# CPSW1_COMMON_0_NUSS register map
Vendor: Texas Instruments
Peripheral module from a debugger description file (folder J7_AHP).
Registers are 32-bit, read-write, reset 0x0 unless marked. A register's access mark holds for its fields unless they carry their own. Offsets are as the file gives them; lines under a group give offsets from that group; [hi:lo] are bit positions; {n}, {i} and the like mark numbered series; 'fields as' and 'values as' point back to an identical list; <NAME> marks a mode.

## CPSW1_COMMON_0_NUSS (part 1 of 2)
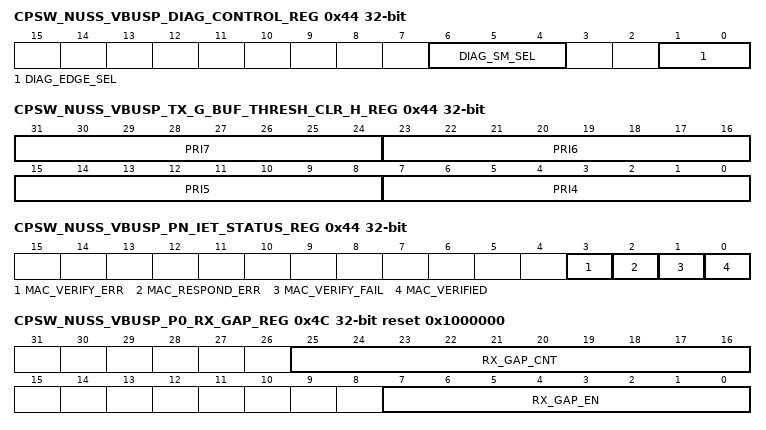
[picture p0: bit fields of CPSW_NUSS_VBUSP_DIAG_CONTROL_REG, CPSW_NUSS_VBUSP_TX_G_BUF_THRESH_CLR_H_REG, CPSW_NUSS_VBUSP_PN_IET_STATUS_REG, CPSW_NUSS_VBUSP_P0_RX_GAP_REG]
0x44 CPSW_NUSS_VBUSP_DIAG_CONTROL_REG
  [6:4] DIAG_SM_SEL — Diagnostic select
  [1:0] DIAG_EDGE_SEL — Diagnostics hold signals edge select
0x44 CPSW_NUSS_VBUSP_USER_ADDR1_REG
  [15:0] USER_ADDR1 — MDIO USER Address 1
0x44 CPSW_NUSS_VBUSP_TX_G_BUF_THRESH_CLR_H_REG
  [8n-25:8n-32] PRI{n} (n=4..7) — Priority Based Flow Control Global Buffer Usage Threshold for Priority {n}
0x44 CPSW_NUSS_VBUSP_PN_IET_STATUS_REG ro
  [3] MAC_VERIFY_ERR — IET MAC VERIFY ERROR
  [2] MAC_RESPOND_ERR — IET MAC RESPONSE ERROR
  [1] MAC_VERIFY_FAIL — IET MAC VERIFY FAIL
  [0] MAC_VERIFIED — IET MAC VERIFIED
0x44 CPSW_NUSS_VBUSP_TXDEFERREDFRAMES
  [31:0] COUNT — Total number of deferred frames transmitted
0x44 CPSW_NUSS_VBUSP_TS_LOAD_HIGH_VAL_REG
  [31:0] TS_LOAD_VAL — Time stamp load high value
0x48 CPSW_NUSS_VBUSP_DIAG_STATUS_REG ro
  [15:0] DIAG_STATUS — Diagnostics status
0x48 CPSW_NUSS_VBUSP_PN_IET_VERIFY_REG reset 0x1312D0
  [23:0] MAC_VERIFY_CNT — IET MAC VERIFY COUNT
0x48 CPSW_NUSS_VBUSP_TXCOLLISIONFRAMES
  [31:0] COUNT — Total number of transmitted frames experiencing a collision
0x48 CPSW_NUSS_VBUSP_TS_COMP_HIGH_VAL_REG
  [31:0] TS_COMP_HIGH_VAL — Time stamp comparison high value
0x4C CPSW_NUSS_VBUSP_P0_RX_GAP_REG reset 0x1000000
  [25:16] RX_GAP_CNT — Port 0 Receive Gap Count
  [7:0] RX_GAP_EN — Port 0 Receive Gap Enable
0x4C CPSW_NUSS_VBUSP_TXSINGLECOLLFRAMES
  [31:0] COUNT — Total number of transmitted frames experiencing a single collision
0x4C CPSW_NUSS_VBUSP_TS_ADD_VAL_REG
  [2:0] ADD_VAL — Add Value
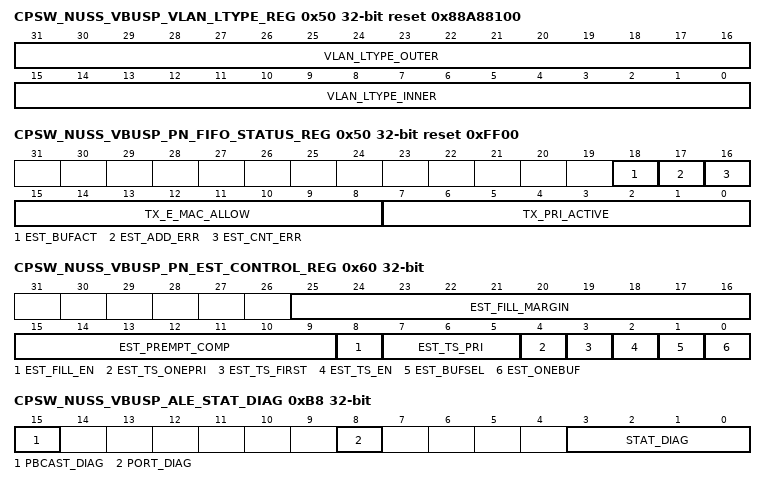
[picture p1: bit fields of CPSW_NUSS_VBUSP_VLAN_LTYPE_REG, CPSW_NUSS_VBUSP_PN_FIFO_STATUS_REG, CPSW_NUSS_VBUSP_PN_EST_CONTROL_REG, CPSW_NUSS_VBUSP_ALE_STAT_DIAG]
0x50 CPSW_NUSS_VBUSP_VLAN_LTYPE_REG reset 0x88A88100
  [31:16] VLAN_LTYPE_OUTER — Outer VLAN LType
  [15:0] VLAN_LTYPE_INNER — Inner VLAN LType
0x50 CPSW_NUSS_VBUSP_P0_FIFO_STATUS_REG ro
  [7:0] TX_PRI_ACTIVE — Port 0 FIFO Status
0x50 CPSW_NUSS_VBUSP_PN_FIFO_STATUS_REG ro reset 0xFF00
  [18] EST_BUFACT — Transmit FIFO EST Buffer Active
  [17] EST_ADD_ERR — Transmit FIFO EST Address Error
  [16] EST_CNT_ERR — Transmit FIFO EST Count Error
  [15:8] TX_E_MAC_ALLOW — Transmit FIFO Express Queue Priority Allow
  [7:0] TX_PRI_ACTIVE — Transmit FIFO Priority Active
0x50 CPSW_NUSS_VBUSP_TXMULTCOLLFRAMES
  [31:0] COUNT — Total number of transmitted frames experiencing multiple collisions
0x50 CPSW_NUSS_VBUSP_TS_PPM_LOW_VAL_REG
  [31:0] TS_PPM_LOW_VAL — Time stamp PPM Low value
0x54 CPSW_NUSS_VBUSP_EST_TS_DOMAIN_REG
  [7:0] EST_TS_DOMAIN — Enhanced Scheduled Traffic Host Event Domain
0x54 CPSW_NUSS_VBUSP_TXEXCESSIVECOLLISIONS
  [31:0] COUNT — Total number of transmitted frames abandoned due to excessive collisions
0x54 CPSW_NUSS_VBUSP_TS_PPM_HIGH_VAL_REG
  [9:0] TS_PPM_HIGH_VAL — Time stamp PPM High value
0x58 CPSW_NUSS_VBUSP_TXLATECOLLISIONS
  [31:0] COUNT — Total number of transmitted frames abandoned due to a late collision
0x58 CPSW_NUSS_VBUSP_TS_NUDGE_VAL_REG
  [7:0] TS_NUDGE_VAL — Time stamp Nudge value
0x5C CPSW_NUSS_VBUSP_RXIPGERROR
  [31:0] COUNT — Total number of receive inter-packet gap errors (10G only)
0x60 CPSW_NUSS_VBUSP_PN_EST_CONTROL_REG
  [25:16] EST_FILL_MARGIN — Transmit FIFO EST Fill Margin
  [15:9] EST_PREMPT_COMP — Transmit FIFO EST Prempt Comparision Value
  [8] EST_FILL_EN — Transmit FIFO EST Fill Enable
  [7:5] EST_TS_PRI — Transmit FIFO EST TimeStamp Priority
  [4] EST_TS_ONEPRI — Transmit FIFO EST TimeStamp One Priority
  [3] EST_TS_FIRST — Transmit FIFO EST TimeStamp First Express Packet
  [2] EST_TS_EN — Transmit FIFO EST TimeStamp Enable
  [1] EST_BUFSEL — Transmit FIFO EST Buffer Select
  [0] EST_ONEBUF — Transmit FIFO EST One Buffer
0x60 CPSW_NUSS_VBUSP_TXCARRIERSENSEERRORS
  [31:0] COUNT — Total number of transmitted frames that experienced a carrier loss
0x64 CPSW_NUSS_VBUSP_TXOCTETS
  [31:0] COUNT — Total number of bytes in all good frames transmitted
0x64 CPSW_NUSS_VBUSP_TXOCTETS
  [31:0] COUNT — Total number of bytes in all good frames transmitted
0x68 CPSW_NUSS_VBUSP_OCTETFRAMES64
  [31:0] COUNT — Total number of 64-byte frames received and transmitted
0x68 CPSW_NUSS_VBUSP_OCTETFRAMES64
  fields as CPSW_NUSS_VBUSP_OCTETFRAMES64
0x6C CPSW_NUSS_VBUSP_OCTETFRAMES65T127
  [31:0] COUNT — Total number of frames of size 65 to 127 bytes received and transmitted
0x6C CPSW_NUSS_VBUSP_OCTETFRAMES65T127
  fields as CPSW_NUSS_VBUSP_OCTETFRAMES65T127
0x70 CPSW_NUSS_VBUSP_OCTETFRAMES128T255
  [31:0] COUNT — Total number of frames of size 128 to 255 bytes received and transmitted
0x70 CPSW_NUSS_VBUSP_OCTETFRAMES128T255
  fields as CPSW_NUSS_VBUSP_OCTETFRAMES128T255
0x74 CPSW_NUSS_VBUSP_OCTETFRAMES256T511
  [31:0] COUNT — Total number of frames of size 256 to 511 bytes received and transmitted
0x74 CPSW_NUSS_VBUSP_OCTETFRAMES256T511
  fields as CPSW_NUSS_VBUSP_OCTETFRAMES256T511
0x78 CPSW_NUSS_VBUSP_OCTETFRAMES512T1023
  [31:0] COUNT — Total number of frames of size 512 to 1023 bytes received and transmitted
0x78 CPSW_NUSS_VBUSP_OCTETFRAMES512T1023
  fields as CPSW_NUSS_VBUSP_OCTETFRAMES512T1023
0x7C CPSW_NUSS_VBUSP_OCTETFRAMES1024TUP
  [31:0] COUNT — Total number of frames of size 1024 to rx_maxlen bytes received and 1024 bytes or greater transmitted
0x7C CPSW_NUSS_VBUSP_OCTETFRAMES1024TUP
  fields as CPSW_NUSS_VBUSP_OCTETFRAMES1024TUP
0x80 CPSW_NUSS_VBUSP_NETOCTETS
  [31:0] COUNT — Total number of bytes received and transmitted
0x80 CPSW_NUSS_VBUSP_NETOCTETS
  [31:0] COUNT — Total number of bytes received and transmitted
0x84 CPSW_NUSS_VBUSP_RX_BOTTOM_OF_FIFO_DROP
  [31:0] COUNT — Receive Bottom of FIFO Drop
0x84 CPSW_NUSS_VBUSP_RX_BOTTOM_OF_FIFO_DROP
  [31:0] COUNT — Receive Bottom of FIFO Drop
0x88 CPSW_NUSS_VBUSP_PORTMASK_DROP
  [31:0] COUNT — Total number of dropped frames received due to portmask
0x88 CPSW_NUSS_VBUSP_PORTMASK_DROP
  fields as CPSW_NUSS_VBUSP_PORTMASK_DROP
0x8C CPSW_NUSS_VBUSP_RX_TOP_OF_FIFO_DROP
  [31:0] COUNT — Receive Top of FIFO Drop
0x8C CPSW_NUSS_VBUSP_RX_TOP_OF_FIFO_DROP
  [31:0] COUNT — Receive Top of FIFO Drop
0x90 CPSW_NUSS_VBUSP_ALE_RATE_LIMIT_DROP
  [31:0] COUNT — Total number of dropped frames due to ALE Rate Limiting
0x90 CPSW_NUSS_VBUSP_ALE_RATE_LIMIT_DROP
  fields as CPSW_NUSS_VBUSP_ALE_RATE_LIMIT_DROP
0x90 CPSW_NUSS_VBUSP_ALE_UVLAN_MEMBER
  [1:0] UVLAN_MEMBER_LIST — Unknown VLAN Member List - Each bit represents the port member status for unknown VLANs.
0x94 CPSW_NUSS_VBUSP_ALE_VID_INGRESS_DROP
  [31:0] COUNT — Total number of dropped frames due to ALE VID Ingress
0x94 CPSW_NUSS_VBUSP_ALE_VID_INGRESS_DROP
  [31:0] COUNT — Total number of dropped frames due to ALE VID Ingress
0x94 CPSW_NUSS_VBUSP_ALE_UVLAN_URCAST
  [1:0] UVLAN_UNREG_MCAST_FLOOD_MASK — Unknown VLAN Unregister Multicast Flood Mask - Each bit represents the port to which unregistered multicast are sent for unregistered VLANs.
0x98 CPSW_NUSS_VBUSP_ALE_DA_EQ_SA_DROP
  [31:0] COUNT — Total number of dropped frames due to DA=SA
0x98 CPSW_NUSS_VBUSP_ALE_DA_EQ_SA_DROP
  [31:0] COUNT — Total number of dropped frames due to DA=SA
0x98 CPSW_NUSS_VBUSP_ALE_UVLAN_RMCAST
  [1:0] UVLAN_REG_MCAST_FLOOD_MASK — Unknown VLAN Register Multicast Flood Mask - Each bit represents the port to which registered multicast are sent for unregistered VLANs. This field is ANDed with the registered multicast mask to determine the destinations for unregistered VLANs.
0x9C CPSW_NUSS_VBUSP_ALE_BLOCK_DROP
  [31:0] COUNT — Total number of dropped frames due to ALE Block Mode
0x9C CPSW_NUSS_VBUSP_ALE_BLOCK_DROP
  [31:0] COUNT — Total number of dropped frames due to ALE Block Mode
0x9C CPSW_NUSS_VBUSP_ALE_UVLAN_UNTAG
  [1:0] UVLAN_FORCE_UNTAGGED_EGRESS — Unknown VLAN Force Untagged Egress Mask - Each bit represents the port where the VLAN will be removed for unregistered VLANs.
0xA0 CPSW_NUSS_VBUSP_ALE_SECURE_DROP
  [31:0] COUNT — Total number of dropped frames due to ALE Secure Mode
0xA0 CPSW_NUSS_VBUSP_ALE_SECURE_DROP
  [31:0] COUNT — Total number of dropped frames due to ALE Secure Mode
0xA4 CPSW_NUSS_VBUSP_ALE_AUTH_DROP
  [31:0] COUNT — Total number of dropped frames due to ALE Authentication
0xA4 CPSW_NUSS_VBUSP_ALE_AUTH_DROP
  fields as CPSW_NUSS_VBUSP_ALE_AUTH_DROP
0xA8 CPSW_NUSS_VBUSP_ALE_UNKN_UNI
  [31:0] COUNT — ALE Receive Unknown Unicast
0xA8 CPSW_NUSS_VBUSP_ALE_UNKN_UNI
  [31:0] COUNT — ALE Receive Unknown Unicast
0xAC CPSW_NUSS_VBUSP_ALE_UNKN_UNI_BCNT
  [31:0] COUNT — ALE Receive Unknown Unicast Bytecount
0xAC CPSW_NUSS_VBUSP_ALE_UNKN_UNI_BCNT
  [31:0] COUNT — ALE Receive Unknown Unicast Bytecount
0xB0 CPSW_NUSS_VBUSP_ALE_UNKN_MLT
  [31:0] COUNT — ALE Receive Unknown Multicast
0xB0 CPSW_NUSS_VBUSP_ALE_UNKN_MLT
  [31:0] COUNT — ALE Receive Unknown Multicast
0xB4 CPSW_NUSS_VBUSP_ALE_UNKN_MLT_BCNT
  [31:0] COUNT — ALE Receive Unknown Multicast Bytecount
0xB4 CPSW_NUSS_VBUSP_ALE_UNKN_MLT_BCNT
  [31:0] COUNT — ALE Receive Unknown Multicast Bytecount
0xB8 CPSW_NUSS_VBUSP_ALE_UNKN_BRD
  [31:0] COUNT — ALE Receive Unknown Broadcast
0xB8 CPSW_NUSS_VBUSP_ALE_UNKN_BRD
  [31:0] COUNT — ALE Receive Unknown Broadcast
0xB8 CPSW_NUSS_VBUSP_ALE_STAT_DIAG
  [15] PBCAST_DIAG — When set and the ~iport_diag is set to zero, will allow all ports to see the same stat diagnostic increment.
  [8] PORT_DIAG — The port selected that a received packet will cause the selected error to increment
  [3:0] STAT_DIAG — When non-zero will cause the selected statistic to increment on the next frame received. For the selected Port. 0: Disabled 1: Destination Equal Source Drop Stat will count 2: VLAN Ingress Check Drop Stat will count 3: Source Multicast Drop Stat will count 4: Dual VLAN Drop Stat will count 5: Ether Type length error Drop Stat will count 6: Next Hop Limit Drop Stat will count 7: IPv4 Fragment Drop Stat will count 8: Classifier Hit Stat will count 9: Classifier Red Drop Stat will count 10: Classifier Yellow Drop Stat will count 11: ALE Overflow Drop Stat will count 12: Rate Limit Drop Stat will count 13: Blocked Address Drop Stat will count 14: Secure Address Drop Stat will count 15: Authorization Drop Stat will count
0xBC CPSW_NUSS_VBUSP_ALE_UNKN_BRD_BCNT
  [31:0] COUNT — ALE Receive Unknown Broadcast Bytecount
0xBC CPSW_NUSS_VBUSP_ALE_UNKN_BRD_BCNT
  [31:0] COUNT — ALE Receive Unknown Broadcast Bytecount
0xBC CPSW_NUSS_VBUSP_ALE_OAM_LB_CTRL
  [1:0] OAM_LB_CTRL — The ~ioam_lb_ctrl allows any port to be put into OAM loopback, that is any packet received will be returned to the same port with an egressop of 0xFF which swaps the source and destination address. BPDUs will still flow through as normal so that OAM can be remotly requested and disabled.
0xC0 CPSW_NUSS_VBUSP_ALE_POL_MATCH
  [31:0] COUNT — ALE Policer Matched
0xC0 CPSW_NUSS_VBUSP_ALE_POL_MATCH
  [31:0] COUNT — ALE Policer Matched
0xC0 CPSW_NUSS_VBUSP_ALE_MSK_MUX0 ro reset 0x3
  [1:0] VLAN_MASK_MUX_0 — VLAN Mask Mux x - When selected by the VLAN lookup table entry FwdUnRegIdx or FwdAllRegIdx is used as the FwdUnRegMask or FwdUnRegMask values anded with the member list to determine the forwarding of packets. The Value of vlan_mask_mux_0 is read only and set to all ones for all ports.
0xC4 CPSW_NUSS_VBUSP_ALE_POL_MATCH_RED
  [31:0] COUNT — ALE Policer Matched and Condition Red
0xC4 CPSW_NUSS_VBUSP_ALE_POL_MATCH_RED
  [31:0] COUNT — ALE Policer Matched and Condition Red
0xC4 CPSW_NUSS_VBUSP_I1_ALE_MSK_MUX1
  [1:0] I1_REG_VLAN_MASK_MUX_1 — VLAN Mask Mux x - When selected by the VLAN lookup table entry FwdUnRegIdx or FwdAllRegIdx is used as the FwdUnRegMask or FwdUnRegMask values anded with the member list to determine the forwarding of packets. The Value of vlan_mask_mux_0 is read only and set to all ones for all ports.
0xC8 CPSW_NUSS_VBUSP_ALE_POL_MATCH_YELLOW
  [31:0] COUNT — ALE Policer Matched and Condition Yellow
0xC8 CPSW_NUSS_VBUSP_ALE_POL_MATCH_YELLOW
  [31:0] COUNT — ALE Policer Matched and Condition Yellow
0xCC CPSW_NUSS_VBUSP_ALE_MULT_SA_DROP
  [31:0] COUNT — ALE Multicast Source Address drop
0xCC CPSW_NUSS_VBUSP_ALE_MULT_SA_DROP
  [31:0] COUNT — ALE Multicast Source Address drop
0xD0 CPSW_NUSS_VBUSP_ALE_DUAL_VLAN_DROP
  [31:0] COUNT — ALE Dual VLAN drop
0xD0 CPSW_NUSS_VBUSP_ALE_DUAL_VLAN_DROP
  [31:0] COUNT — ALE Dual VLAN drop
0xD4 CPSW_NUSS_VBUSP_ALE_LEN_ERROR_DROP
  [31:0] COUNT — ALE Length Error drop
0xD4 CPSW_NUSS_VBUSP_ALE_LEN_ERROR_DROP
  [31:0] COUNT — ALE Length Error drop
0xD8 CPSW_NUSS_VBUSP_ALE_IP_NEXT_HDR_DROP
  [31:0] COUNT — ALE Next Header drop
0xD8 CPSW_NUSS_VBUSP_ALE_IP_NEXT_HDR_DROP
  [31:0] COUNT — ALE Next Header drop
0xDC CPSW_NUSS_VBUSP_ALE_IPV4_FRAG_DROP
  [31:0] COUNT — ALE IPV4 Fragment drop
0xDC CPSW_NUSS_VBUSP_ALE_IPV4_FRAG_DROP
  [31:0] COUNT — ALE IPV4 Fragment drop
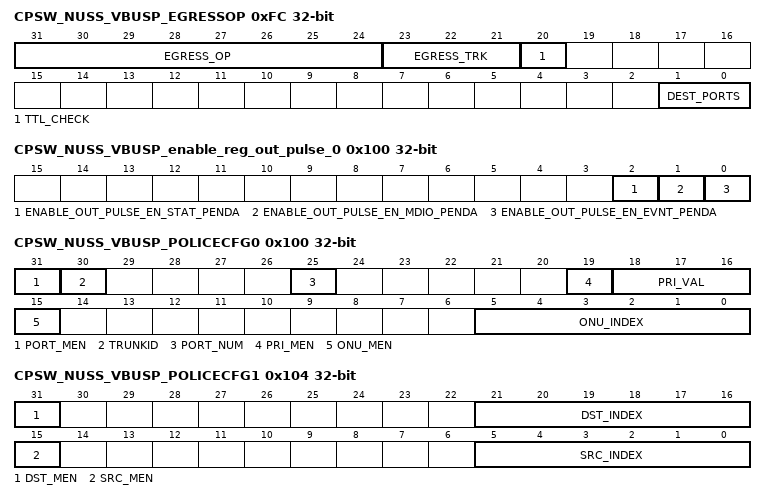
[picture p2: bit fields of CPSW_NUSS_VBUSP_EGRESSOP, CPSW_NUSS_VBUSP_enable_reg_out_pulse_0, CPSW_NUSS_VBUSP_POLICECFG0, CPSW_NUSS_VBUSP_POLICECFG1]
0xFC CPSW_NUSS_VBUSP_EGRESSOP
  [31:24] EGRESS_OP — The Egress Operation defines the operation performed by the CPSW Egress Packet Operations 0: NOP : 1-n: Defines which egress Operation will be performed. This allows Inter VLAN routing to be configured for high bandwidth traffic, reducing CPU load. 0xff: Swap SA and DA of packet, this is intended to allow OAM diagnostics for a link.
  [23:21] EGRESS_TRK — The Egress Trunk Index is the calculated trunk index from the SA, DA or VLAN if modified to that InterVLAN routing will work on trunks as well. The DA, SA and VLAN are ignored for trunk generation on InterVLAN Routing so that this field is the index generated from the Egress Op replacements elclusive or'd together into a three bit index.
  [20] TTL_CHECK — The TTL Check will cause any packet that fails TTL checks to not be routed to the Inter VLAN Routing sub functions. The packet will be routed to the host it was destined to.
  [1:0] DEST_PORTS — The Destination Ports is a list of the ports the classified packet will be set to. If a destination is a Trunk, all the port bits for that trunck must be set.
0x100 CPSW_NUSS_VBUSP_enable_reg_out_pulse_0 access not given
  [2] ENABLE_OUT_PULSE_EN_STAT_PENDA — Enable Set for out_pulse_en_stat_penda (access R/W1TS)
  [1] ENABLE_OUT_PULSE_EN_MDIO_PENDA — Enable Set for out_pulse_en_mdio_penda (access R/W1TS)
  [0] ENABLE_OUT_PULSE_EN_EVNT_PENDA — Enable Set for out_pulse_en_evnt_penda (access R/W1TS)
{0x100+4i} CPSW_NUSS_VBUSP_TX_PRI{i}_MAXLEN_REG reset 0x7E8 (i=0..7)
  [13:0] TX_PRI{i}_MAXLEN — Transmit Priority {i} Maximum Length
0x100 CPSW_NUSS_VBUSP_POLICECFG0
  [31] PORT_MEN — Port Match Enable - Enabled port match for the selected policing/classifier entry
  [30] TRUNKID — Trunk ID - When set indicates the port number is a trunk group.
  [25] PORT_NUM — Port Number - Specifies the port address to match for the selected policing/classifier entry
  [19] PRI_MEN — Priority Match Enable - Enables frame priority match for the selected policing/classifier entry
  [18:16] PRI_VAL — Priority Value - Specifies the frame priority to match for the selected policing/classifier entry
  [15] ONU_MEN — OUI Match Enable - Enables frame ONU address match for the selected policing/classifier entry
  [5:0] ONU_INDEX — OUI Table Entry Index - Specifies the ALE ONU address lookup table index to match for the selected policing/classifier entry
0x104 CPSW_NUSS_VBUSP_POLICECFG1
  [31] DST_MEN — Destination Address Match Enable - Enables frame L2 destination address match for the selected policing/classifier entry
  [21:16] DST_INDEX — Destination Address Table Entry Index - Specifies the ALE L2 destination address lookup table index to match for the selected policing/classifier entry
  [15] SRC_MEN — Source Address Match Enable - Enables frame L2 source address match for the selected policing/classifier entry
  [5:0] SRC_INDEX — Source Address Table Entry Index - Specifies the ALE L2 source address lookup table index to match for the selected policing/classifier entry
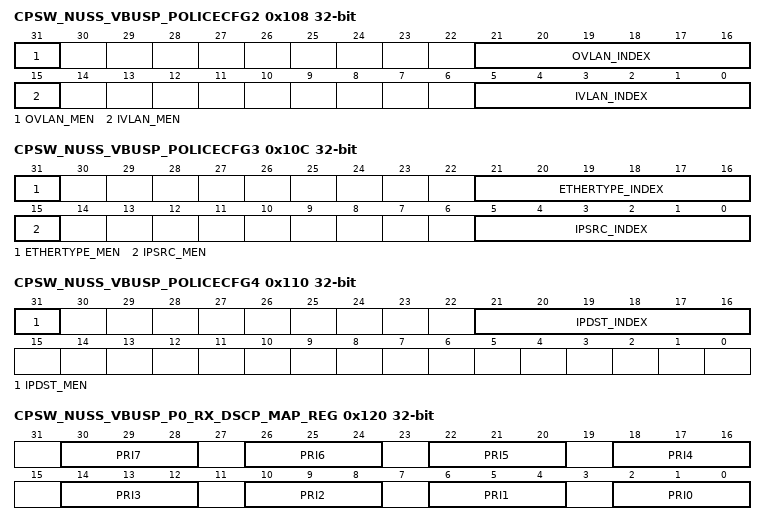
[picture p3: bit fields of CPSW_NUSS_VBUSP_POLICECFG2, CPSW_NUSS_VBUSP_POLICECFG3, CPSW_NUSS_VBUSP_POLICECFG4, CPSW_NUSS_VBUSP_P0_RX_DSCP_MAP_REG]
0x108 CPSW_NUSS_VBUSP_POLICECFG2
  [31] OVLAN_MEN — Outer VLAN Match Enable - Enables frame Outer VLAN address match for the selected policing/classifier entry
  [21:16] OVLAN_INDEX — Outer VLAN Table Entry Index - Specifies the ALE Outer VLAN address lookup table index to match for the selected policing/classifier entry
  [15] IVLAN_MEN — Inner VLAN Match Enable - Enables frame Inner VLAN address match for the selected policing/classifier entry
  [5:0] IVLAN_INDEX — Inner VLAN Table Entry Index - Specifies the ALE Inner VLAN address lookup table index to match for the selected policing/classifier entry
0x10C CPSW_NUSS_VBUSP_POLICECFG3
  [31] ETHERTYPE_MEN — EtherType Match Enable - Enables frame Ether Type match for the selected policing/classifier entry
  [21:16] ETHERTYPE_INDEX — EtherType Table Entry Index - Specifies the ALE Ether Type lookup table index to match for the selected policing/classifier entry
  [15] IPSRC_MEN — IP Source Address Match Enable - Enables frame IP Source address match for the selected policing/classifier entry
  [5:0] IPSRC_INDEX — IP Source Address Table Entry Index - Specifies the ALE IP Source address lookup table index to match for the selected policing/classifier entry
0x110 CPSW_NUSS_VBUSP_POLICECFG4
  [31] IPDST_MEN — IP Destination Address Match Enable - Enables frame IP Destination address match for the selected policing/classifier entry
  [21:16] IPDST_INDEX — IP Destination Address Table Entry Index - Specifies the ALE IP Destination address lookup table index to match for the selected policing/classifier entry
0x118 CPSW_NUSS_VBUSP_POLICECFG6
  [31:0] PIR_IDLE_INC_VAL — Peak Information Rate Idle Increment Value - The number added to the PIR counter every clock cycle. If zero the PIR counter is disabled and packets will never be marked or processed as RED.
0x11C CPSW_NUSS_VBUSP_POLICECFG7
  [31:0] CIR_IDLE_INC_VAL — Committed Information Idle Increment Value - The number added to the CIR counter every clock cycle. If zero the CIR counter is disabled and packets will never be marked or processed as YELLOW.
0x120 CPSW_NUSS_VBUSP_P0_RX_DSCP_MAP_REG
  [4n+2:4n] PRI{n} (n=0..7) — A DSCP IPV4/V6 packet TOS of N*8+{n} is mapped to this received priority
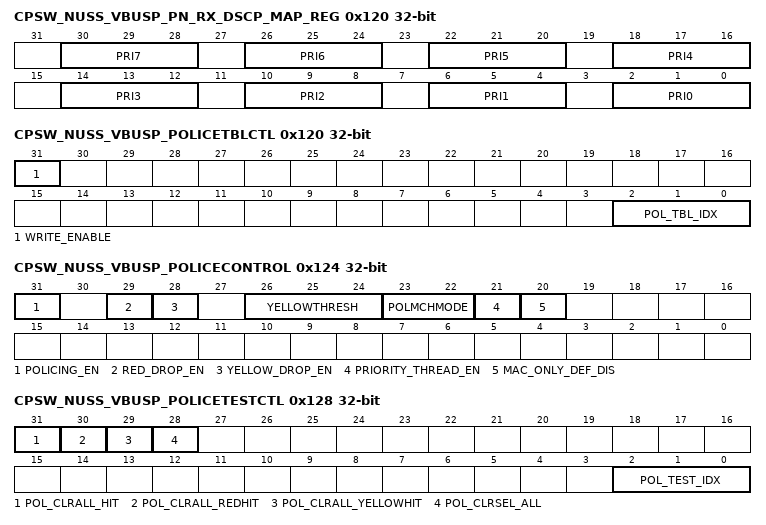
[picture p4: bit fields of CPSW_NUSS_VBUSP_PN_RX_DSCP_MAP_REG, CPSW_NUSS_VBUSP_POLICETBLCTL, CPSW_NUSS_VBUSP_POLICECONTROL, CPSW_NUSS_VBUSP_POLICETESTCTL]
0x120 CPSW_NUSS_VBUSP_PN_RX_DSCP_MAP_REG
  fields as CPSW_NUSS_VBUSP_P0_RX_DSCP_MAP_REG
0x120 CPSW_NUSS_VBUSP_POLICETBLCTL
  [31] WRITE_ENABLE — Write Enable - Setting this bit will write the POLICECFG0-7 to the ~ipol_tbl_idx selected policing/classifier entry. Clearing this bit will read the ~ipol_tbl_idx selected policing/classifier entry into the POLICECFG0-7 registers.
  [2:0] POL_TBL_IDX — Policer Entry Index - This field specifies the policing/classifier entry to be read or written. When writing to this field without setting the ~iwrite_enable=1 will cause the selected policing/classifier entry to be loaded into the POLICECFG0-7 registers. When writing to this field with setting the ~iwrite_enable=1 will cause the selected policing/classifier entry to be updated from the POLICECFG0-7 registers.
0x124 CPSW_NUSS_VBUSP_POLICECONTROL
  [31] POLICING_EN — Policing Enable - Enables the policing to color the packets, this also enables red or yellow drop capabilities.
  [29] RED_DROP_EN — RED Drop Enable - Enables the ALE to drop the red colored packets.
  [28] YELLOW_DROP_EN — WELLOW Drop Enable - Enables the ALE to drop yellow packets based on the ~iyellowthresh value. This field would normally not be used as to let the switch drop packets at a buffer threshold instead. In the event that the switch does not enable buffer threshold dropping, YELLOW packets can be dropped based on this feature.
  [26:24] YELLOWTHRESH — Yellow Threshold - When set enables a portion of the yellow packets to be dropped based on the ~iyellow_drop_en enable. 0-100% 1=50% 2-33% 3-25% 4=20% 5-17% 6-14% 7-13%
  [23:22] POLMCHMODE — Policing Match Mode - This field determines what happens to packets that fail to hit any policing/classifier entry. 0 - No Hit packets are marked GREEN 1 - No Hit packets are marked YELLOW 2 - No Hit packets are marked RED 3 - No Hit packets are marked based on policing/classifier entry=0 state.
  [21] PRIORITY_THREAD_EN — Priority Thread Enable - This field determines if priority is OR'd to the default thread when no classifiers hit and the default thread is enabled.
  [20] MAC_ONLY_DEF_DIS — MAC Only Default Disable - This field when set disables the default thread on MAC Only Ports. That is the default thread will be {port,priority}. If the traffic matches a classifier with a thread mapping, the classifier thread mapping still occurs.
0x128 CPSW_NUSS_VBUSP_POLICETESTCTL
  [31] POL_CLRALL_HIT — Policer Clear - This bit clears all the policing/classifier hit bits. This bit is self clearing. This can be used to test the fact that a policing/classifier entry has been hit.
  [30] POL_CLRALL_REDHIT — Policer Clear RED - This bit clears all the policing/classifier RED hit bits. This bit is self clearing. This can be used to test the fact that a policing/classifier entry has been hit during a RED condition.
  [29] POL_CLRALL_YELLOWHIT — Policer Clear YELLOW - This bit clears all the policing/classifier YELLOW hit bits. This bit is self clearing. This can be used to test the fact that a policing/classifier entry has been hit during a YELLOW condition.
  [28] POL_CLRSEL_ALL — Police Clear Selected - This bit clears the selected policing/classifier hit, redhit and yellowhit bits. This bit is self clearing.
  [2:0] POL_TEST_IDX — Policer Test Index - This field selects which policing/classifier hit bits will be read or written.
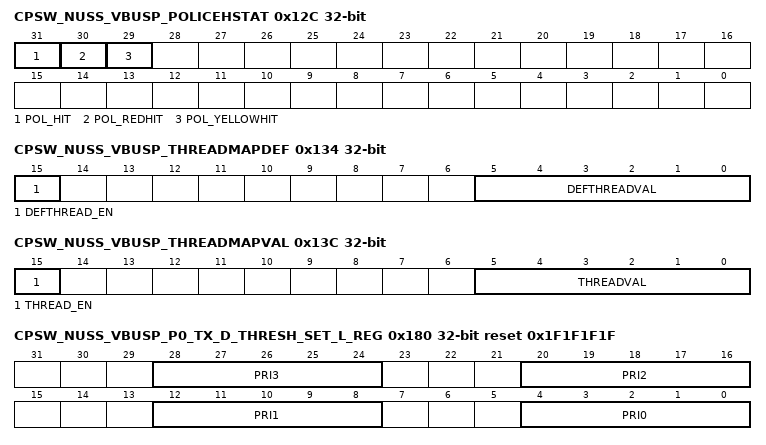
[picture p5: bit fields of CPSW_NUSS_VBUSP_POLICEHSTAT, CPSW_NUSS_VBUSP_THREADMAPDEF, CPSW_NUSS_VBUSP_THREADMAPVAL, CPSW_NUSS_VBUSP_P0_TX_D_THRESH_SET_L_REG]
0x12C CPSW_NUSS_VBUSP_POLICEHSTAT ro
  [31] POL_HIT — Policer Hit - This indicates that the selected policing/classifier via the ~ipol_test_idx field has been hit by a packet seen on any port that matches the policing/classifier entry match.
  [30] POL_REDHIT — Policer Hit RED - This indicates that the selected policing/classifier via the ~ipol_test_idx field has been hit during a RED condition by a packet seen on any port that matches the policing/classifier entry match.
  [29] POL_YELLOWHIT — Policer Hit YELLOW - This indicates that the selected policing/classifier via the ~ipol_test_idx field has been hit during a YELLOW condition by a packet seen on any port that matches the policing/classifier entry match.
0x134 CPSW_NUSS_VBUSP_THREADMAPDEF
  [15] DEFTHREAD_EN — Default Tread Enable - When set the switch will use the ~idefthreadval for the host interface thread ID if no classifier is matched. If clear the switch will generate its own thread ID based on port and priority if there is no classifier match.
  [5:0] DEFTHREADVAL — Default Thread Value - This field specifies the default thread ID value.
0x138 CPSW_NUSS_VBUSP_THREADMAPCTL
  [2:0] CLASSINDEX — Classifier Index - This is the classifier index entry that the thread enable and thread value will be read or written by the ~bTHREADMAPVAL register.
0x13C CPSW_NUSS_VBUSP_THREADMAPVAL
  [15] THREAD_EN — Thread Enable - When set the switch will use the ~ithreadval for the selected classifier match. If clear the the thread ID will be determined by the ~bTHREADMAPDEF register settings.
  [5:0] THREADVAL — Thread Value - This field is the thread ID value that is used to map a classifier hit to thread ID for host traffic.
0x140 CPSW_NUSS_VBUSP_P0_PRI_CIR_REG
  [27:0] PRI_CIR — Priority N CIR
0x140 CPSW_NUSS_VBUSP_PN_PRI_CIR_REG
  [27:0] PRI_CIR — Priority N committed information rate
0x140 CPSW_NUSS_VBUSP_IET_RX_ASSEMBLY_ERROR_REG
  [31:0] IET_RX_ASSEMBLY_ERROR — IET Receive Assembly Error
0x140 CPSW_NUSS_VBUSP_IET_RX_ASSEMBLY_ERROR_REG
  [31:0] IET_RX_ASSEMBLY_ERROR — IET Receive Assembly Error
0x144 CPSW_NUSS_VBUSP_IET_RX_ASSEMBLY_OK_REG
  [31:0] IET_RX_ASSEMBLY_OK — IET Receive Assembly Ok
0x144 CPSW_NUSS_VBUSP_IET_RX_ASSEMBLY_OK_REG
  [31:0] IET_RX_ASSEMBLY_OK — IET Receive Assembly Ok
0x148 CPSW_NUSS_VBUSP_IET_RX_SMD_ERROR_REG
  [31:0] IET_RX_SMD_ERROR — IET Receive Smd Error
0x148 CPSW_NUSS_VBUSP_IET_RX_SMD_ERROR_REG
  [31:0] IET_RX_SMD_ERROR — IET Receive Smd Error
0x14C CPSW_NUSS_VBUSP_IET_RX_FRAG_REG
  [31:0] IET_RX_FRAG — IET Receive Frag
0x14C CPSW_NUSS_VBUSP_IET_RX_FRAG_REG
  [31:0] IET_RX_FRAG — IET Receive Frag
0x150 CPSW_NUSS_VBUSP_IET_TX_HOLD_REG
  [31:0] IET_TX_HOLD — IET Transmit Hold
0x150 CPSW_NUSS_VBUSP_IET_TX_HOLD_REG
  [31:0] IET_TX_HOLD — IET Transmit Hold
0x154 CPSW_NUSS_VBUSP_IET_TX_FRAG_REG
  [31:0] IET_TX_FRAG — IET Transmit Frag
0x154 CPSW_NUSS_VBUSP_IET_TX_FRAG_REG
  [31:0] IET_TX_FRAG — IET Transmit Frag
0x160 CPSW_NUSS_VBUSP_P0_PRI_EIR_REG
  [27:0] PRI_EIR — Priority N EIR
0x160 CPSW_NUSS_VBUSP_PN_PRI_EIR_REG
  [27:0] PRI_EIR — Priority N Excess Information Rate count
0x17C CPSW_NUSS_VBUSP_TX_MEMORY_PROTECT_ERROR
  [7:0] COUNT — Transmit Memory Protect CRC Error
0x17C CPSW_NUSS_VBUSP_TX_MEMORY_PROTECT_ERROR
  [7:0] COUNT — Transmit Memory Protect CRC Error
0x180 CPSW_NUSS_VBUSP_P0_TX_D_THRESH_SET_L_REG reset 0x1F1F1F1F
  [8n+4:8n] PRI{n} (n=0..3) — Port Priority Based Flow Control Threshold Set Value for Priority {n}
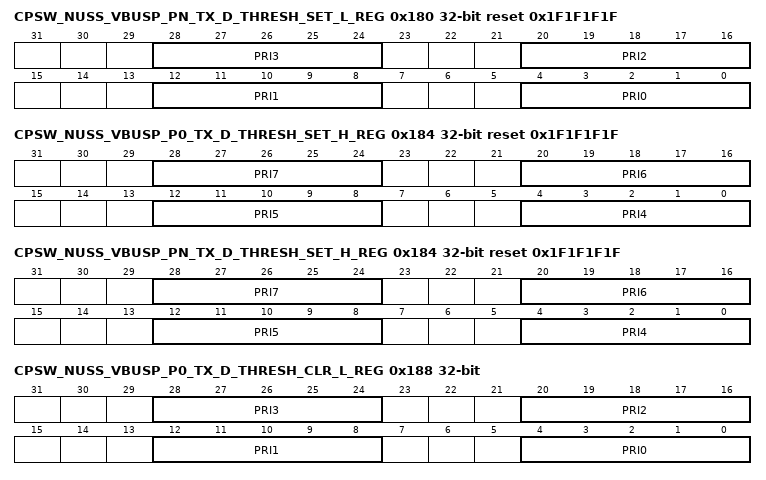
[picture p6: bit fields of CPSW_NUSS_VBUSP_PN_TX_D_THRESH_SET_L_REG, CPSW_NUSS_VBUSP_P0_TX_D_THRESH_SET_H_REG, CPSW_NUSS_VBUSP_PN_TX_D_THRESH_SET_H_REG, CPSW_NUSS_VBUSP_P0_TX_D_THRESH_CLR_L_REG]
0x180 CPSW_NUSS_VBUSP_PN_TX_D_THRESH_SET_L_REG reset 0x1F1F1F1F
  fields as CPSW_NUSS_VBUSP_P0_TX_D_THRESH_SET_L_REG
0x180 CPSW_NUSS_VBUSP_ENET_PN_TX_PRI_REG
  [31:0] PN_TX_PRIN — Enet Port n Priority N Packet Count
0x184 CPSW_NUSS_VBUSP_P0_TX_D_THRESH_SET_H_REG reset 0x1F1F1F1F
  [8n-28:8n-32] PRI{n} (n=4..7) — Port Priority Based Flow Control Threshold Set Value for Priority {n}
0x184 CPSW_NUSS_VBUSP_PN_TX_D_THRESH_SET_H_REG reset 0x1F1F1F1F
  fields as CPSW_NUSS_VBUSP_P0_TX_D_THRESH_SET_H_REG
0x188 CPSW_NUSS_VBUSP_P0_TX_D_THRESH_CLR_L_REG
  [8n+4:8n] PRI{n} (n=0..3) — Port Priority Based Flow Control Threshold Clear Value for Priority {n}
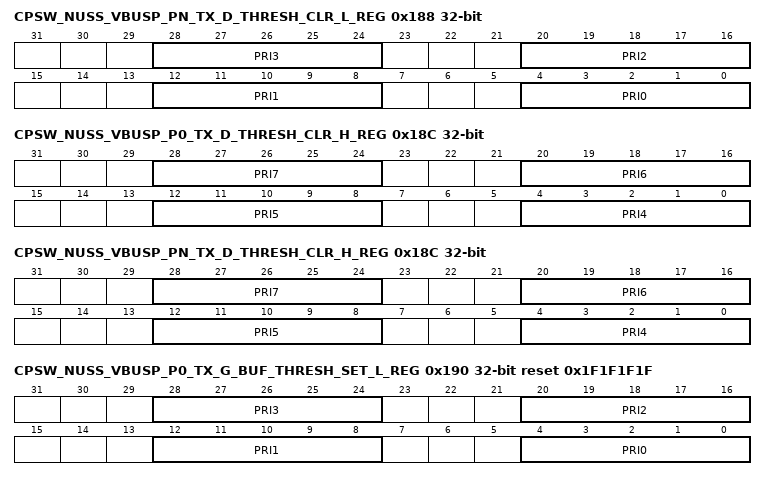
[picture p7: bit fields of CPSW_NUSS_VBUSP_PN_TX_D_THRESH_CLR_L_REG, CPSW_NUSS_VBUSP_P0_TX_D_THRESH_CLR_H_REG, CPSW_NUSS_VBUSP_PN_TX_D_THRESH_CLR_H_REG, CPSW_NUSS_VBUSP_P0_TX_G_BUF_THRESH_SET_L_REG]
0x188 CPSW_NUSS_VBUSP_PN_TX_D_THRESH_CLR_L_REG
  fields as CPSW_NUSS_VBUSP_P0_TX_D_THRESH_CLR_L_REG
0x18C CPSW_NUSS_VBUSP_P0_TX_D_THRESH_CLR_H_REG
  [8n-28:8n-32] PRI{n} (n=4..7) — Port Priority Based Flow Control Threshold Clear Value for Priority {n}
0x18C CPSW_NUSS_VBUSP_PN_TX_D_THRESH_CLR_H_REG
  fields as CPSW_NUSS_VBUSP_P0_TX_D_THRESH_CLR_H_REG
0x190 CPSW_NUSS_VBUSP_P0_TX_G_BUF_THRESH_SET_L_REG reset 0x1F1F1F1F
  fields as CPSW_NUSS_VBUSP_P0_TX_D_THRESH_SET_L_REG
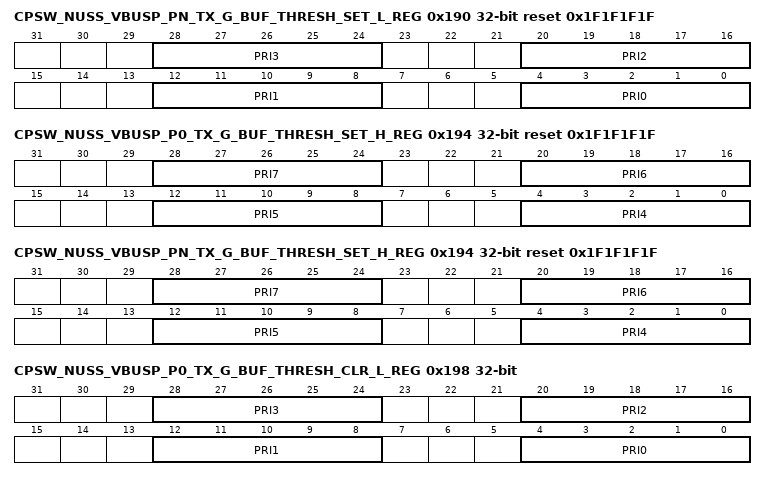
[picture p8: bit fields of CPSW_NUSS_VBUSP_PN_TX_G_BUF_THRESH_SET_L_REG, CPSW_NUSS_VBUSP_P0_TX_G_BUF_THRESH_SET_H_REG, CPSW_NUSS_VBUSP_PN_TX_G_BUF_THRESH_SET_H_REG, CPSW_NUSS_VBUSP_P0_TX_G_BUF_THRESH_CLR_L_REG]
0x190 CPSW_NUSS_VBUSP_PN_TX_G_BUF_THRESH_SET_L_REG reset 0x1F1F1F1F
  fields as CPSW_NUSS_VBUSP_P0_TX_D_THRESH_SET_L_REG
0x194 CPSW_NUSS_VBUSP_P0_TX_G_BUF_THRESH_SET_H_REG reset 0x1F1F1F1F
  fields as CPSW_NUSS_VBUSP_P0_TX_D_THRESH_SET_H_REG
0x194 CPSW_NUSS_VBUSP_PN_TX_G_BUF_THRESH_SET_H_REG reset 0x1F1F1F1F
  fields as CPSW_NUSS_VBUSP_P0_TX_D_THRESH_SET_H_REG
0x198 CPSW_NUSS_VBUSP_P0_TX_G_BUF_THRESH_CLR_L_REG
  fields as CPSW_NUSS_VBUSP_P0_TX_D_THRESH_CLR_L_REG
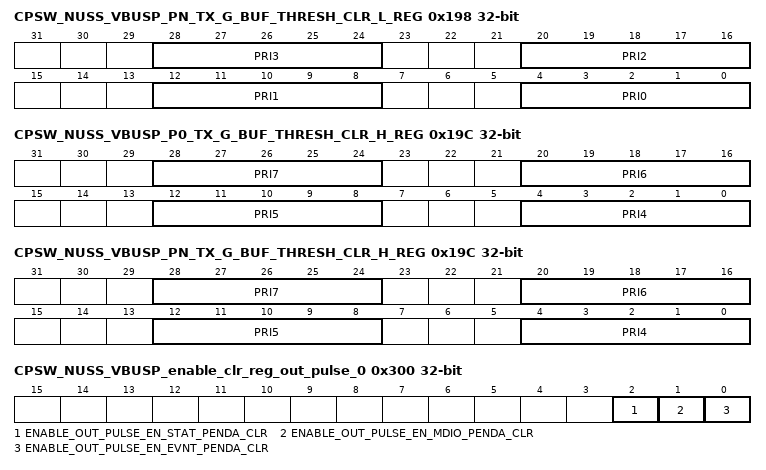
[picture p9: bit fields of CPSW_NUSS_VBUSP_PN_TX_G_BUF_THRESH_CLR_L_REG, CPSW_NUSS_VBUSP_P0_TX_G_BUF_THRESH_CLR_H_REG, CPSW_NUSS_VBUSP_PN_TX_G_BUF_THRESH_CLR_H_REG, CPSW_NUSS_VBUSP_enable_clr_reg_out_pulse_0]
0x198 CPSW_NUSS_VBUSP_PN_TX_G_BUF_THRESH_CLR_L_REG
  fields as CPSW_NUSS_VBUSP_P0_TX_D_THRESH_CLR_L_REG
0x19C CPSW_NUSS_VBUSP_P0_TX_G_BUF_THRESH_CLR_H_REG
  fields as CPSW_NUSS_VBUSP_P0_TX_D_THRESH_CLR_H_REG
0x19C CPSW_NUSS_VBUSP_PN_TX_G_BUF_THRESH_CLR_H_REG
  fields as CPSW_NUSS_VBUSP_P0_TX_D_THRESH_CLR_H_REG
0x1A0 CPSW_NUSS_VBUSP_ENET_PN_TX_PRI_BCNT_REG
  [31:0] PN_TX_PRIN_BCNT — ENET Port n PRIORITY N Packet Byte Count
0x1C0 CPSW_NUSS_VBUSP_ENET_PN_TX_PRI_DROP_REG
  [31:0] PN_TX_PRIN_DROP — ENET Port n PRIORITY N Packet Drop Count
0x1E0 CPSW_NUSS_VBUSP_ENET_PN_TX_PRI_DROP_BCNT_REG
  [31:0] PN_TX_PRIN_DROP_BCNT — ENET Port n PRIORITY N Packet Drop Byte Count
0x300 CPSW_NUSS_VBUSP_enable_clr_reg_out_pulse_0 access not given
  [2] ENABLE_OUT_PULSE_EN_STAT_PENDA_CLR — Enable Clear for out_pulse_en_stat_penda (access R/W1TC)
  [1] ENABLE_OUT_PULSE_EN_MDIO_PENDA_CLR — Enable Clear for out_pulse_en_mdio_penda (access R/W1TC)
  [0] ENABLE_OUT_PULSE_EN_EVNT_PENDA_CLR — Enable Clear for out_pulse_en_evnt_penda (access R/W1TC)
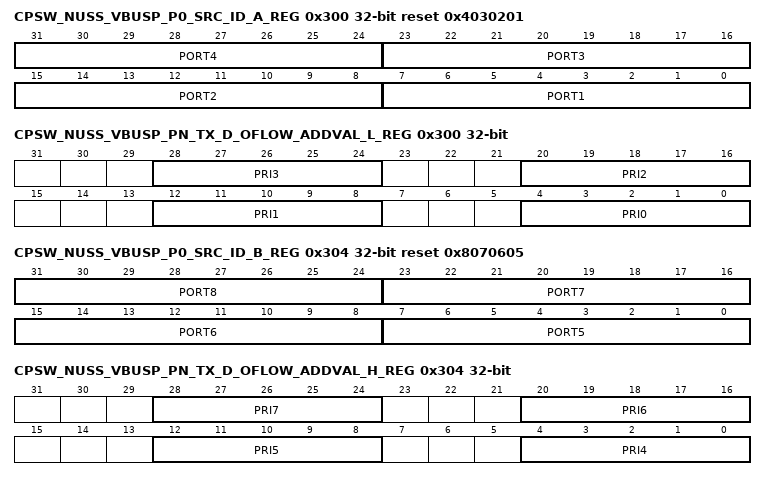
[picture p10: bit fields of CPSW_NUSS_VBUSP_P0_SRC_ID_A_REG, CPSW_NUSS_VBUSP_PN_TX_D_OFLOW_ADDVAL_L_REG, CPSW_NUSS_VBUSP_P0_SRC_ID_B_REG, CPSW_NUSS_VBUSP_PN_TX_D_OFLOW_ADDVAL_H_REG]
0x300 CPSW_NUSS_VBUSP_P0_SRC_ID_A_REG reset 0x4030201
  [8n-1:8n-8] PORT{n} (n=1..4) — Port {n} CPPI Info Word0 Source ID Value
0x300 CPSW_NUSS_VBUSP_PN_TX_D_OFLOW_ADDVAL_L_REG
  [8n+4:8n] PRI{n} (n=0..3) — Port PFC Destination Based Out Flow Add Value for Priority {n}
0x304 CPSW_NUSS_VBUSP_P0_SRC_ID_B_REG reset 0x8070605
  [8n-33:8n-40] PORT{n} (n=5..8) — Port {n} CPPI Info Word0 Source ID Value
0x304 CPSW_NUSS_VBUSP_PN_TX_D_OFLOW_ADDVAL_H_REG
  [8n-28:8n-32] PRI{n} (n=4..7) — Port PFC Destination Based Out Flow Add Value for Priority {n}
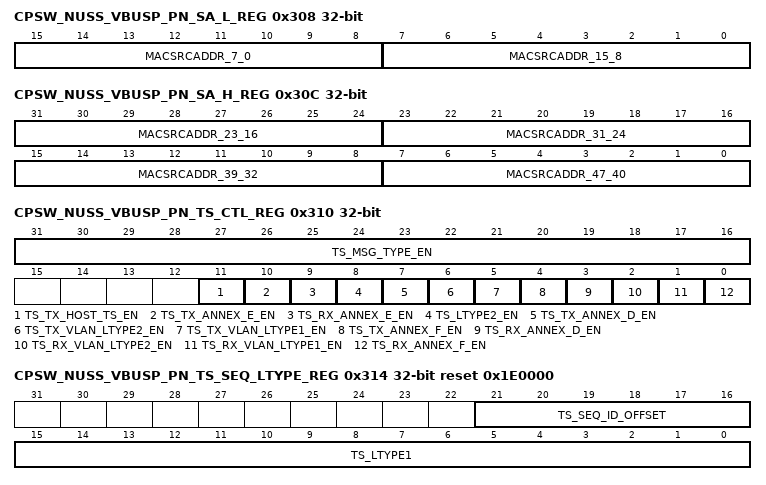
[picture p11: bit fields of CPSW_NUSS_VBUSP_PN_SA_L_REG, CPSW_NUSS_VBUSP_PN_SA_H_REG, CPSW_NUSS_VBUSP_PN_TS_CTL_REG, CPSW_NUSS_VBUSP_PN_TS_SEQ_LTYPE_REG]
0x308 CPSW_NUSS_VBUSP_PN_SA_L_REG
  [15:8] MACSRCADDR_7_0 — Source Address Lower 8 bits
  [7:0] MACSRCADDR_15_8 — Source Address bits 15:8
0x30C CPSW_NUSS_VBUSP_PN_SA_H_REG
  [31:24] MACSRCADDR_23_16 — Source Address bits 23:16
  [23:16] MACSRCADDR_31_24 — Source Address bits 31:24
  [15:8] MACSRCADDR_39_32 — Source Address bits 39:32
  [7:0] MACSRCADDR_47_40 — Source Address bits 47:40
0x310 CPSW_NUSS_VBUSP_PN_TS_CTL_REG
  [31:16] TS_MSG_TYPE_EN — Time Sync Message Type Enable
  [11] TS_TX_HOST_TS_EN — Time Sync Transmit Host Time Stamp Enable
  [10] TS_TX_ANNEX_E_EN — Time Synce Transmit Annex E Enable
  [9] TS_RX_ANNEX_E_EN — Time Synce Receive Annex E Enable
  [8] TS_LTYPE2_EN — Time Sync LTYPE 2 enable transmit and receive
  [7] TS_TX_ANNEX_D_EN — Time Synce Transmit Annex D Enable
  [6] TS_TX_VLAN_LTYPE2_EN — Time Sync Transmit VLAN LTYPE 2 enable
  [5] TS_TX_VLAN_LTYPE1_EN — Time Sync Transmit VLAN LTYPE 1 enable
  [4] TS_TX_ANNEX_F_EN — Time Synce Transmit Annex F Enable
  [3] TS_RX_ANNEX_D_EN — Time Synce Receive Annex D Enable
  [2] TS_RX_VLAN_LTYPE2_EN — Time Sync Receive VLAN LTYPE 2 enable
  [1] TS_RX_VLAN_LTYPE1_EN — Time Sync Receive VLAN LTYPE 1 enable
  [0] TS_RX_ANNEX_F_EN — Time Synce Receive Annex F Enable
0x314 CPSW_NUSS_VBUSP_PN_TS_SEQ_LTYPE_REG reset 0x1E0000
  [21:16] TS_SEQ_ID_OFFSET — Time Sync Sequence ID Offset
  [15:0] TS_LTYPE1 — Time Sync LTYPE1
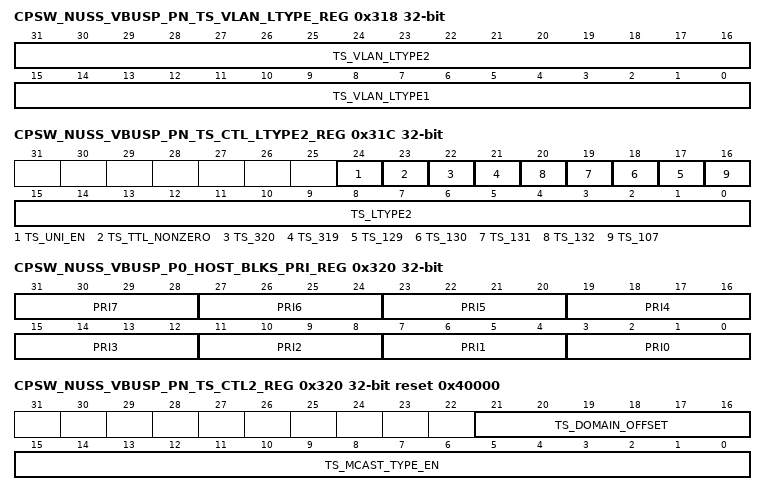
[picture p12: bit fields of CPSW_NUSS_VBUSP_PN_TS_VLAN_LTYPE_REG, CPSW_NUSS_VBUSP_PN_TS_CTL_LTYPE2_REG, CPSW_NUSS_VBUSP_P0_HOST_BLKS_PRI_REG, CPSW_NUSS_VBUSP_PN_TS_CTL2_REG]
0x318 CPSW_NUSS_VBUSP_PN_TS_VLAN_LTYPE_REG
  [31:16] TS_VLAN_LTYPE2 — Time Sync VLAN LTYPE2
  [15:0] TS_VLAN_LTYPE1 — Time Sync VLAN LTYPE1
0x31C CPSW_NUSS_VBUSP_PN_TS_CTL_LTYPE2_REG
  [24] TS_UNI_EN — Time Sync Unicast Enable
  [23] TS_TTL_NONZERO — Time Sync Time to Live Non-zero Enable
  [22] TS_320 — Time Sync Destination IP Address 320 Enable
  [21] TS_319 — Time Sync Destination IP Address 319 Enable
  [n-112] TS_{n} (n=129..132) — Time Sync Destination IP Address {n} Enable
  [16] TS_107 — Time Sync Destination IP Address 107 Enable
  [15:0] TS_LTYPE2 — Time Sync LTYPE2
0x320 CPSW_NUSS_VBUSP_P0_HOST_BLKS_PRI_REG
  [4n+3:4n] PRI{n} (n=0..7) — Priority {n} Host Blocks
0x320 CPSW_NUSS_VBUSP_PN_TS_CTL2_REG reset 0x40000
  [21:16] TS_DOMAIN_OFFSET — Time Sync Domain Offset
  [15:0] TS_MCAST_TYPE_EN — Time Sync Multicast Destination Address Type Enable
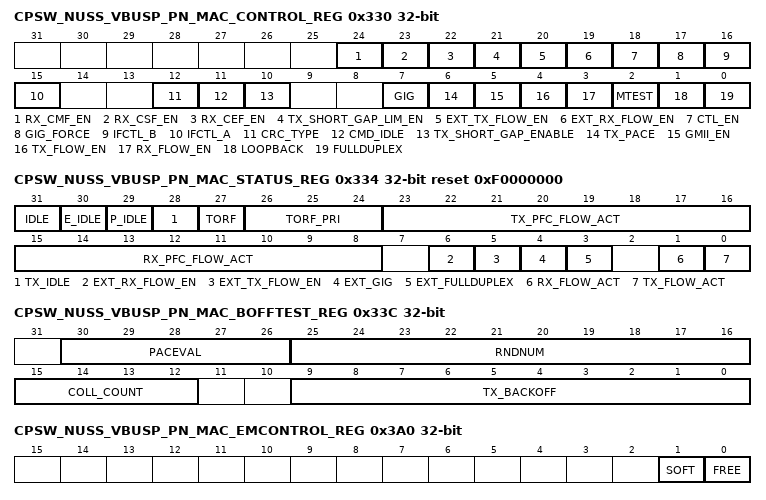
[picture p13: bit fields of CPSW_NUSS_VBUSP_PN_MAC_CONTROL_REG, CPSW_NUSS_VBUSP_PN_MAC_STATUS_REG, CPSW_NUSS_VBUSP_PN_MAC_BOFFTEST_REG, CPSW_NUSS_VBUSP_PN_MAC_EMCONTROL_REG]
0x330 CPSW_NUSS_VBUSP_PN_MAC_CONTROL_REG
  [24] RX_CMF_EN — RX Copy MAC Control Frames Enable
  [23] RX_CSF_EN — RX Copy Short Frames Enable
  [22] RX_CEF_EN — RX Copy Error Frames Enable
  [21] TX_SHORT_GAP_LIM_EN — Transmit Short Gap Limit Enable
  [20] EXT_TX_FLOW_EN — External Transmit Flow Control Enable
  [19] EXT_RX_FLOW_EN — External Receive Flow Control Enable
  [18] CTL_EN — Control Enable
  [17] GIG_FORCE — Gigabit Mode Force
  [16] IFCTL_B — Interface Control B
  [15] IFCTL_A — Interface Control A
  [12] CRC_TYPE — Port CRC Type
  [11] CMD_IDLE — Command Idle
  [10] TX_SHORT_GAP_ENABLE — Transmit Short Gap Enable
  [7] GIG — Gigabit Mode
  [6] TX_PACE — Transmit Pacing Enable
  [5] GMII_EN — GMII Enable
  [4] TX_FLOW_EN — Transmit Flow Control Enable
  [3] RX_FLOW_EN — Receive Flow Control Enable
  [2] MTEST — Manufacturing Test Mode
  [1] LOOPBACK — Loop Back Mode
  [0] FULLDUPLEX — Full Duplex mode
0x334 CPSW_NUSS_VBUSP_PN_MAC_STATUS_REG ro reset 0xF0000000
  [31] IDLE — cpxmac_sl IDLE
  [30] E_IDLE — cpxmac_sl IDLE
  [29] P_IDLE — cpxmac_sl IDLE
  [28] TX_IDLE — cpxmac_sl IDLE
  [27] TORF — Top of receive FIFO flow control trigger occurred. This bit is write one to clear.
  [26:24] TORF_PRI — The lowest priority that caused top of receive FIFO flow control trigger since the last write to clear. This field is write 0x7 to clear.
  [23:16] TX_PFC_FLOW_ACT — Transmit Priority Based Flow Control Active (priority 7 down to 0)
  [15:8] RX_PFC_FLOW_ACT — Receive Priority Based Flow Control Active (priority 7 down to 0)
  [6] EXT_RX_FLOW_EN — External Transmit Flow Control Enable
  [5] EXT_TX_FLOW_EN — External Receive Flow Control Enable
  [4] EXT_GIG — External GIG mode
  [3] EXT_FULLDUPLEX — External Fullduplex
  [1] RX_FLOW_ACT — Receive Flow Control Active
  [0] TX_FLOW_ACT — Transmit Flow Control Active
0x338 CPSW_NUSS_VBUSP_PN_MAC_SOFT_RESET_REG
  [0] SOFT_RESET — Software reset
0x33C CPSW_NUSS_VBUSP_PN_MAC_BOFFTEST_REG access per field
  [30:26] PACEVAL rw — Pacing Register Current Value
  [25:16] RNDNUM rw — Backoff Random Number Generator
  [15:12] COLL_COUNT ro — Collision Count
  [9:0] TX_BACKOFF ro — Backoff Count
0x340 CPSW_NUSS_VBUSP_PN_MAC_RX_PAUSETIMER_REG
  [15:0] RX_PAUSETIMER — RX Pause Timer Value
0x350 CPSW_NUSS_VBUSP_PN_MAC_RXN_PAUSETIMER_REG
  [15:0] RX_PAUSETIMER — RX Pause Timer Value
0x370 CPSW_NUSS_VBUSP_PN_MAC_TX_PAUSETIMER_REG
  [15:0] TX_PAUSETIMER — TX Pause Timer Value
0x380 CPSW_NUSS_VBUSP_PN_MAC_TXN_PAUSETIMER_REG
  [15:0] TX_PAUSETIMER — TX Pause Timer Value
0x3A0 CPSW_NUSS_VBUSP_PN_MAC_EMCONTROL_REG
  [1] SOFT — Emulation Soft Bit
  [0] FREE — Emulation Free Bit
0x3A4 CPSW_NUSS_VBUSP_PN_MAC_TX_GAP_REG reset 0xC
  [15:0] TX_GAP — Transmit Inter-Packet Gap
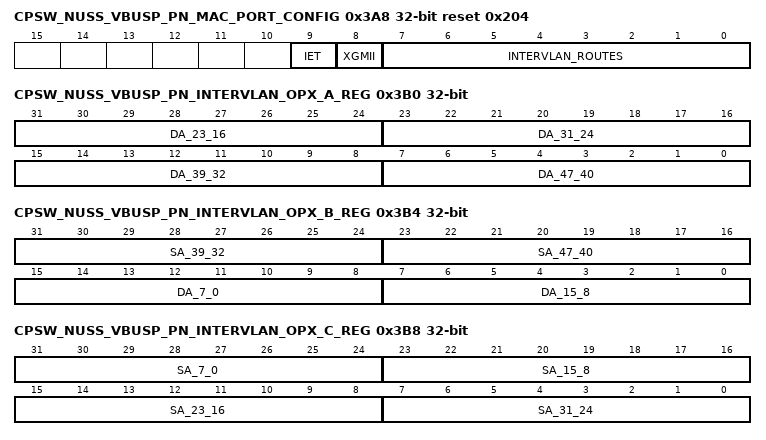
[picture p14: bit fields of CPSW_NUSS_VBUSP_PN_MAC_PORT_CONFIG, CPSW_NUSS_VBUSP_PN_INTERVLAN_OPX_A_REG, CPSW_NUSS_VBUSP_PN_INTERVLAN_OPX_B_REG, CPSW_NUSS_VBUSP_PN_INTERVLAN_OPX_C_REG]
0x3A8 CPSW_NUSS_VBUSP_PN_MAC_PORT_CONFIG ro reset 0x204
  [9] IET — IET support
  [8] XGMII — XGMII support
  [7:0] INTERVLAN_ROUTES — The number of InterVLAN routes
0x3AC CPSW_NUSS_VBUSP_PN_INTERVLAN_OPX_POINTER_REG
  [2:0] POINTER — InterVLAN location pointer: This field points to the InterVLAN location that will be read/written by accesses to Enet_Pn_InterVLANx_A/B.
0x3B0 CPSW_NUSS_VBUSP_PN_INTERVLAN_OPX_A_REG
  [31:24] DA_23_16 — Destination Address bits 23:16
  [23:16] DA_31_24 — Destination Address bits 31:24
  [15:8] DA_39_32 — Destination Address bits 39:32
  [7:0] DA_47_40 — Destination Address bits 47:40
0x3B4 CPSW_NUSS_VBUSP_PN_INTERVLAN_OPX_B_REG
  [31:24] SA_39_32 — Source Address bits 39:32
  [23:16] SA_47_40 — Source Address bits 47:40
  [15:8] DA_7_0 — Destination Address bits 7:0
  [7:0] DA_15_8 — Destination Address bits 15:8
0x3B8 CPSW_NUSS_VBUSP_PN_INTERVLAN_OPX_C_REG
  [31:24] SA_7_0 — Source Address bits 7:0
  [23:16] SA_15_8 — Source Address bits 15:8
  [15:8] SA_23_16 — Source Address bits 23:16
  [7:0] SA_31_24 — Source Address bits 31:24
0x3BC CPSW_NUSS_VBUSP_PN_INTERVLAN_OPX_D_REG
  [15] DECREMENT_TTL — Decrement Time To Live: When set, the Time To Live (TTL) field in the header is decremented.
  [14] DEST_FORCE_UNTAGGED_EGRESS — Destination VLAN Force Untagged Egress: When set, this bit indicates that the VLAN should be removed on egress for the routed packet.
  [13] REPLACE_DA_SA — Replace Destination Address and Source Address: When set this bit indicates that the routed packet destination address should be replaced by da[47:0] and the source address should be replaced by sa[47:0].
  [12] REPLACE_VID — Replace VLAN ID: When set this bit indicates that the VLAN ID should be replaced for the routed packet.
  [11:0] VID — VLAN ID
0x500 CPSW_NUSS_VBUSP_status_reg_out_pulse_0 ro
  [2] STATUS_OUT_PULSE_STAT_PENDA — Status for out_pulse_en_stat_penda
  [1] STATUS_OUT_PULSE_MDIO_PENDA — Status for out_pulse_en_mdio_penda
  [0] STATUS_OUT_PULSE_EVNT_PENDA — Status for out_pulse_en_evnt_penda
0xA80 CPSW_NUSS_VBUSP_intr_vector_reg_out_pulse ro
  [31:0] INTR_VECTOR_OUT_PULSE — Interrupt Vector
